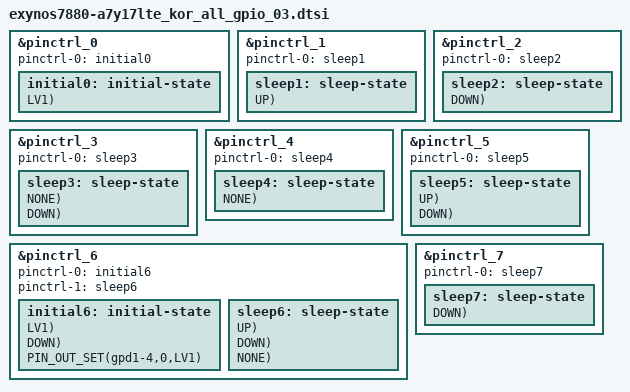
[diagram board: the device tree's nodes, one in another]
/*
 * Copyright (c) 2015 Samsung Electronics Co., Ltd.
 *		http://www.samsung.com
 *
 * This program is free software; you can redistribute it and/or modify
 * it under the terms of the GNU General Public License version 2 as
 * published by the Free Software Foundation.
*/

#include "exynos_gpio_config_macros.dtsi"

/* 0x139F_0000(ALIVE): gpa0~3, gpq0 */
&pinctrl_0 {
	/*
	 * Note:
	 *   Please do not make "sleep-state" node for GPA group GPIOs.
	 *   GPA group doesn't have power-down status.
	 */
	pinctrl-names = "default";
	pinctrl-0 = <&initial0>;
	initial0: initial-state {
		PIN_IN(gpa0-7, NONE, LV1);	/* SSP_MCU_INT1 */
		PIN_IN(gpa2-5, NONE, LV1);	/* SSP_MCU_INT2 */
		PIN_IN(gpa3-2, NONE, LV1);	/* NC with Ext.PU */

		PIN_IN(gpq0-1, DOWN, LV1);	/* NC */

		PIN_IN(etc1-0, NONE, LV1);	/* XOM_0 */
		PIN_IN(etc1-1, NONE, LV1);	/* XOM_1 */	
	};
};

/* 0x1063_0000(CCORE): gpm0 */
&pinctrl_1 {
	pinctrl-names = "sleep";
	pinctrl-0 = <&sleep1>;
	sleep1: sleep-state {
		PIN_SLP(gpm0-0, PREV, UP);	/* PMIC_SDA_1P8 */
		PIN_SLP(gpm0-1, PREV, UP);	/* PMIC_SCL_1P8 */
	};
};

/* 0x148C_0000(DISPAUD): gpz0~2 */
&pinctrl_2 {
	pinctrl-names = "sleep";
	pinctrl-0 = <&sleep2>;
	sleep2: sleep-state {
		PIN_SLP(gpz0-0, INPUT, DOWN);	/* BT_PCM_SYNC */
		PIN_SLP(gpz0-1, INPUT, DOWN);	/* BT_PCM_CLK */
		PIN_SLP(gpz0-2, INPUT, DOWN);	/* BT_PCM_D_OUT */
		PIN_SLP(gpz0-3, INPUT, DOWN);	/* BT_PCM_D_IN */

		PIN_SLP(gpz1-0, INPUT, DOWN);	/* BB_I2S_LRCK(SPK_I2S_SYNC) */
		PIN_SLP(gpz1-1, INPUT, DOWN);	/* SPK_I2S_CLK */
		PIN_SLP(gpz1-2, INPUT, DOWN);	/* BB_I2S_DI */
		PIN_SLP(gpz1-3, INPUT, DOWN);	/* BB_I2S_DO(SPK_I2S_OUT) */
		PIN_SLP(gpz1-4, INPUT, DOWN);	/* CODEC_24M */
		PIN_SLP(gpz1-5, INPUT, DOWN);	/* SPK_I2C_IN */

		PIN_SLP(gpz2-0, INPUT, DOWN);	/* NC */
		PIN_SLP(gpz2-1, INPUT, DOWN);	/* NC */
		PIN_SLP(gpz2-2, INPUT, DOWN);	/* NC */
		PIN_SLP(gpz2-3, INPUT, DOWN);	/* NC */
	};
};

/* 0x139E_0000(ESE): gpc7 */
&pinctrl_3 {
	pinctrl-names = "sleep";
	pinctrl-0 = <&sleep3>;
	sleep3: sleep-state {
		PIN_SLP(gpc7-0, OUT0, NONE);	/* BTP_SPI_CLK */
		PIN_SLP(gpc7-1, OUT0, NONE);	/* BTP_SPI_CS_N */
		PIN_SLP(gpc7-2, INPUT, DOWN);	/* BTP_SPI_MISO */
		PIN_SLP(gpc7-3, OUT0, NONE);	/* BTP_SPI_MOSI */

		PIN_SLP(gpc7-4, INPUT, DOWN);	/* ESE_SPI_CS_N */
	};
};

/* 0x1375_0000(FSYS): gpr0~4 */
&pinctrl_4 {
	pinctrl-names = "sleep";
	pinctrl-0 = <&sleep4>;
	sleep4: sleep-state {
		PIN_SLP(gpr0-1, INPUT, NONE);		/*eMMC_CMD*/
	};
};

/* 0x139C_0000(NFC): gpc2 */
&pinctrl_5 {
	pinctrl-names = "sleep";
	pinctrl-0 = <&sleep5>;
	sleep5: sleep-state {
		PIN_SLP(gpc2-2, PREV, UP);	/* NFC_PD */
		PIN_SLP(gpc2-3, PREV, DOWN);	/* NFC_CLKREQ */
	};
};

/* 0x139B_0000(TOP): gpb0, gpc0~1, gpc4~6, gpc8~9, gpd1~5, gpe0, gpf0~4 */
&pinctrl_6 {
	pinctrl-names = "default","sleep";
	pinctrl-0 = <&initial6>;
	pinctrl-1 = <&sleep6>;
	initial6: initial-state {
		PIN_IN(gpc6-1, DOWN, LV1);	/* NC */

		PIN_IN(gpc8-0, DOWN, LV1);	/* NC(SUB_CHG_SDA_1P8) */
		PIN_IN(gpc8-1, DOWN, LV1);	/* NC(SUB_CHG_SCL_1P8) */

		PIN_IN(gpd2-1, DOWN, LV1);	/* IFPMIC_RSTB */

		PIN_OUT_SET_PULL(gpd2-3, 0, LV1, DOWN);	/* MOTOR_EN */
		PIN_IN(gpd2-4, NONE, LV1);	/* HW_REV0 */
		PIN_IN(gpd2-5, NONE, LV1);	/* HW_REV1 */

		PIN_IN(gpd3-0, NONE, LV1);	/* HW_REV2 */
		PIN_IN(gpd3-1, NONE, LV1);	/* HW_REV3 */

		PIN_OUT_SET(gpd1-4,0,LV1);	/*VCONN_EN */
		PIN_OUT_SET(gpd1-5, 1, LV1);	/* SSP_AP_INT */
		PIN_OUT_SET(gpf4-2, 1, LV1);	/* SSP_RST */
	};
	sleep6: sleep-state {
		PIN_SLP(gpb0-0, INPUT, UP);	/* BT_UART_RXD */
		PIN_SLP(gpb0-1, OUT1, UP);	/* BT_UART_TXD */
		PIN_SLP(gpb0-2, INPUT, UP);	/* BT_UART_CTS */
		PIN_SLP(gpb0-3, OUT1, UP);	/* BT_UART_RTS */

		PIN_SLP(gpc0-1, INPUT, DOWN);	/* VIB_PWM */
		PIN_SLP(gpc0-2, INPUT, UP);	/* EMMC_RTS_N */

		PIN_SLP(gpc1-0, PREV, NONE);	/* IF_PMIC_SDA_1P8 */
		PIN_SLP(gpc1-1, PREV, NONE);	/* IF_PMIC_SCL_1P8 */
		PIN_SLP(gpc1-2, INPUT, DOWN);	/* VTCAM_AF_EEP_SDA_1P8 */
		PIN_SLP(gpc1-3, INPUT, DOWN);	/* VTCAM_AF_EEP_SCL_1P8 */

		PIN_SLP(gpc4-0, INPUT, NONE);	/* FG_SDA_1P8 */
		PIN_SLP(gpc4-1, INPUT, NONE);	/* FG_SCL_1P8 */
		PIN_SLP(gpc4-2, OUT1, UP);	/* SHUB_SPI_CLK */
		PIN_SLP(gpc4-3, OUT1, UP);	/* SHUB_SPI_SS_N */

		PIN_SLP(gpc5-0, INPUT, DOWN);	/* SHUB_SPI_MISO */
		PIN_SLP(gpc5-1, OUT1, UP);	/* SHUB_SPI_MOSI */

		PIN_SLP(gpc6-0, INPUT, DOWN);	/* ESE_SPI_CLK */
		PIN_SLP(gpc6-1, INPUT, DOWN);	/* NC */
		PIN_SLP(gpc6-2, INPUT, DOWN);	/* ESE_SPI_MISO */
		PIN_SLP(gpc6-3, INPUT, DOWN);	/* ESE_SPI_MOSI */

		PIN_SLP(gpc8-0, INPUT, NONE);	/* SUB_CHG_SDA_1P8 */
		PIN_SLP(gpc8-1, INPUT, NONE);	/* SUB_CHG_SCL_1P8 */

		PIN_SLP(gpc9-0, INPUT, NONE);	/* SPK_AMP_SDA_1P8 */
		PIN_SLP(gpc9-1, INPUT, NONE);	/* SPK_AMP_SCL_1P8 */

		PIN_SLP(gpd1-0, PREV, NONE);	/* WRSTB_IN */
		PIN_SLP(gpd1-2, PREV, NONE);	/* DS_DET */
		PIN_SLP(gpd1-3, INPUT, DOWN);	/* NTP_CHECK */
		PIN_SLP(gpd1-4, PREV, NONE);	/* VCONN_EN */
		PIN_SLP(gpd1-5, PREV, NONE);	/* SSP_AP_INT */
		PIN_SLP(gpd1-6, PREV, NONE);	/* NFC_1P8_EN */

		PIN_SLP(gpd2-0, PREV, NONE);	/* SHUB_BOOT0 */
		PIN_SLP(gpd2-1, INPUT, DOWN);	/* IFPMIC_RSTB */
		PIN_SLP(gpd2-2, INPUT, DOWN);	/* DISP_TE */
		PIN_SLP(gpd2-3, OUT0, DOWN);	/* HRM_EN */
		PIN_SLP(gpd2-4, INPUT, NONE);	/* HW_REV0 */
		PIN_SLP(gpd2-5, INPUT, NONE);	/* HW_REV1 */

		PIN_SLP(gpd3-0, INPUT, NONE);	/* HW_REV2 */
		PIN_SLP(gpd3-1, INPUT, NONE);	/* HW_REV3 */
		PIN_SLP(gpd3-2, PREV, NONE);	/* CAM_FLASH_EN */
		PIN_SLP(gpd3-3, PREV, NONE);	/* WLAN_DCDC_EN */
		PIN_SLP(gpd3-4, PREV, NONE);	/* MLCD_RST_N */
		PIN_SLP(gpd3-5, INPUT, DOWN);	/* CAM_RST_N */
		PIN_SLP(gpd3-6, PREV, NONE);	/* WLAN_EN */
		PIN_SLP(gpd3-7, OUT0, NONE);	/* VTCAM_2P8_A_EN */

		PIN_SLP(gpd4-0, OUT0, NONE);	/* CAM_2P8_A_EN */
		PIN_SLP(gpd4-1, PREV, DOWN);	/* NFC_FIRM */
		PIN_SLP(gpd4-2, PREV, NONE);	/* BT_EN */
		PIN_SLP(gpd4-3, OUT0, DOWN);	/* HRM_IO_EN */
		PIN_SLP(gpd4-4, INPUT, DOWN);	/* CAM_AF_2P8_EN */
		PIN_SLP(gpd4-5, PREV, NONE);	/* GPS_HUB_EN */
		PIN_SLP(gpd4-6, INPUT, DOWN);	/* VTCAM_RST_N */

		PIN_SLP(gpd5-0, INPUT, DOWN);	/* VTCAM_1P0_EN */
		PIN_SLP(gpd5-2, PREV, DOWN);	/* BTP_LDO_EN */
		PIN_SLP(gpd5-3, PREV, DOWN);	/* BTP_RST_N */
		PIN_SLP(gpd5-4, OUT0, NONE);	/* CAM_1P0_EN */

		PIN_SLP(gpe0-0, INPUT, DOWN);	/* CAM_MCLK */
		PIN_SLP(gpe0-1, INPUT, DOWN);	/* VTCAM_MCLK */
		PIN_SLP(gpe0-2, INPUT, DOWN);	/* DISP_TE */

		PIN_SLP(gpf0-0, INPUT, DOWN);	/* CAM_SDA_1P8 */
		PIN_SLP(gpf0-1, INPUT, DOWN);	/* CAM_SCL_1P8 */
		PIN_SLP(gpf0-2, INPUT, DOWN);	/* VTCAM_SDA_1P8 */
		PIN_SLP(gpf0-3, INPUT, DOWN);	/* VTCAM_SCL_1P8 */

		PIN_SLP(gpf1-0, INPUT, DOWN);	/* CAM_AF_EEP_SDA_1P8 */
		PIN_SLP(gpf1-1, INPUT, DOWN);	/* CAM_AF_EEP_SCL_1P8 */

		PIN_SLP(gpf2-0, INPUT, NONE);	/* HRM_SDA_1P8 */
		PIN_SLP(gpf2-1, INPUT, NONE);	/* HRM_SCL_1P8 */

		PIN_SLP(gpf3-0, INPUT, DOWN);	/* FROM_SPI_CLK */
		PIN_SLP(gpf3-1, INPUT, DOWN);	/* FROM_SPI_SS_N */
		PIN_SLP(gpf3-2, INPUT, DOWN);	/* FROM_SPI_MISO */
		PIN_SLP(gpf3-3, INPUT, DOWN);	/* FROM_SPI_MOSI */

		PIN_SLP(gpf4-0, INPUT, DOWN);	/* COMP_SPI_CLK */
		PIN_SLP(gpf4-1, INPUT, DOWN);	/* COMP_SPI_SS_N */
		PIN_SLP(gpf4-2, PREV, NONE);	/* SSP_RST */
		PIN_SLP(gpf4-3, PREV, DOWN);	/* MST_PWR_EN */
		PIN_SLP(gpf4-4, INPUT, DOWN);	/* COMP_MCLK */
	};
};

/* 0x139D_0000(MST): gpc3 */
&pinctrl_7 {
	pinctrl-names = "sleep";
	pinctrl-0= <&sleep7>;
	sleep7: sleep-state {
		PIN_SLP(gpc3-0, PREV, DOWN);	/* MST_DATA_B(EN) */
		PIN_SLP(gpc3-1, PREV, DOWN);	/* MST_DATA_A */
		PIN_SLP(gpc3-2, INPUT, DOWN);	/* TSP_INT */
	};
};
